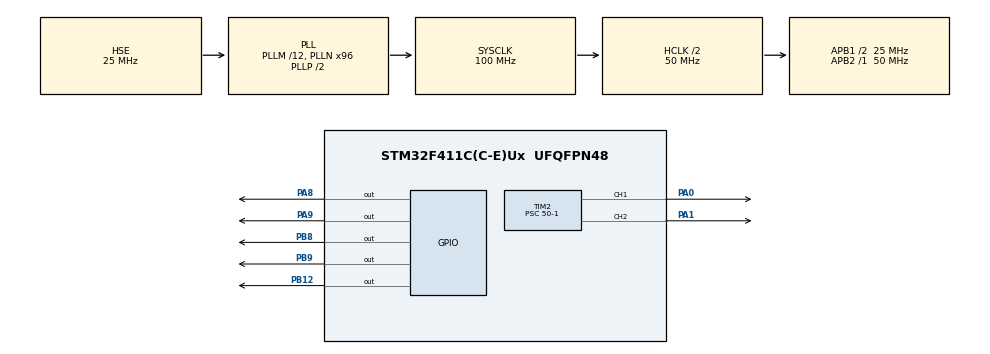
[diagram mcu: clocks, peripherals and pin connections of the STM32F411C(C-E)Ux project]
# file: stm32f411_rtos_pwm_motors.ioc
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FREERTOS.Tasks01=pwm01,24,128,startPwm01,Default,NULL,Dynamic,NULL,NULL;pwm02,8,128,startPwm02,Default,NULL,Dynamic,NULL,NULL;led01,8,128,startLed01,Default,NULL,Dynamic,NULL,NULL
FREERTOS.configUSE_NEWLIB_REENTRANT=1
Mcu.Family=STM32F4
Mcu.Name=STM32F411C(C-E)Ux
Mcu.Package=UFQFPN48
NVIC.PriorityGroup=NVIC_PRIORITYGROUP_4
NVIC.TIM5_IRQn=true\:15\:0\:false\:false\:true\:false\:false\:true\:true
NVIC.TimeBase=TIM5_IRQn
NVIC.TimeBaseIP=TIM5
PA0-WKUP.Signal=S_TIM2_CH1_ETR
PA1.Signal=S_TIM2_CH2
PA13.Mode=Serial_Wire
PA13.Signal=SYS_JTMS-SWDIO
PA14.Mode=Serial_Wire
PA14.Signal=SYS_JTCK-SWCLK
PA8.Signal=GPIO_Output
PA9.Signal=GPIO_Output
PB12.Signal=GPIO_Output
PB8.Signal=GPIO_Output
PB9.Signal=GPIO_Output
PH0\ -\ OSC_IN.Mode=HSE-External-Oscillator
PH0\ -\ OSC_IN.Signal=RCC_OSC_IN
PH1\ -\ OSC_OUT.Mode=HSE-External-Oscillator
PH1\ -\ OSC_OUT.Signal=RCC_OSC_OUT
ProjectManager.HeapSize=0x200
ProjectManager.StackSize=0x400
ProjectManager.TargetToolchain=STM32CubeIDE
RCC.48MHZClocksFreq_Value=50000000
RCC.AHBCLKDivider=RCC_SYSCLK_DIV2
RCC.AHBFreq_Value=50000000
RCC.APB1CLKDivider=RCC_HCLK_DIV2
RCC.APB1Freq_Value=25000000
RCC.APB1TimFreq_Value=50000000
RCC.APB2Freq_Value=50000000
RCC.APB2TimFreq_Value=50000000
RCC.CortexFreq_Value=50000000
RCC.HCLKFreq_Value=50000000
RCC.HSE_VALUE=25000000
RCC.HSI_VALUE=16000000
RCC.LSE_VALUE=32768
RCC.PLLM=12
RCC.PLLN=96
RCC.PLLSourceVirtual=RCC_PLLSOURCE_HSE
RCC.SYSCLKFreq_VALUE=100000000
RCC.SYSCLKSource=RCC_SYSCLKSOURCE_PLLCLK
RCC.VCOOutputFreq_Value=200000000
SH.S_TIM2_CH1_ETR.0=TIM2_CH1,PWM Generation1 CH1
SH.S_TIM2_CH2.0=TIM2_CH2,PWM Generation2 CH2
TIM2.Channel-PWM\ Generation1\ CH1=TIM_CHANNEL_1
TIM2.Channel-PWM\ Generation2\ CH2=TIM_CHANNEL_2
TIM2.Period=1000-1
TIM2.Prescaler=50-1
VP_FREERTOS_VS_CMSIS_V2.Mode=CMSIS_V2
VP_SYS_VS_tim5.Mode=TIM5
board=custom

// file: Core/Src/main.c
/* USER CODE BEGIN Header */
/**
  ******************************************************************************
  * @file           : main.c
  * @brief          : Main program body
  ******************************************************************************
  * @attention
  *
  * Copyright (c) 2023 STMicroelectronics.
  * All rights reserved.
  *
  * This software is licensed under terms that can be found in the LICENSE file
  * in the root directory of this software component.
  * If no LICENSE file comes with this software, it is provided AS-IS.
  *
  ******************************************************************************
  */
/* USER CODE END Header */
#include "main.h"
#include "cmsis_os.h"

/* USER CODE BEGIN PD */
// Define the size of the message queue
/* USER CODE END PD */

TIM_HandleTypeDef htim2;

/* Definitions for pwm01 */
osThreadId_t pwm01Handle;
const osThreadAttr_t pwm01_attributes = {
  .name = "pwm01",
  .stack_size = 128 * 4,
  .priority = (osPriority_t) osPriorityNormal,
};
/* Definitions for pwm02 */
osThreadId_t pwm02Handle;
const osThreadAttr_t pwm02_attributes = {
  .name = "pwm02",
  .stack_size = 128 * 4,
  .priority = (osPriority_t) osPriorityLow,
};
/* Definitions for led01 */
osThreadId_t led01Handle;
const osThreadAttr_t led01_attributes = {
  .name = "led01",
  .stack_size = 128 * 4,
  .priority = (osPriority_t) osPriorityLow,
};
/* USER CODE BEGIN PV */
// Structure to hold motor speed data

/* USER CODE END PV */

void SystemClock_Config(void);
static void MX_GPIO_Init(void);
static void MX_TIM2_Init(void);
void startPwm01(void *argument);
void startPwm02(void *argument);
void startLed01(void *argument);

int main(void)
{

  /* MCU Configuration--------------------------------------------------------*/

  /* Reset of all peripherals, Initializes the Flash interface and the Systick. */
  HAL_Init();

  /* Configure the system clock */
  SystemClock_Config();

  /* Initialize all configured peripherals */
  MX_GPIO_Init();
  MX_TIM2_Init();

  /* Init scheduler */
  osKernelInitialize();

  /* Create the thread(s) */
  /* creation of pwm01 */
  pwm01Handle = osThreadNew(startPwm01, NULL, &pwm01_attributes);

  /* creation of pwm02 */
  pwm02Handle = osThreadNew(startPwm02, NULL, &pwm02_attributes);

  /* creation of led01 */
  led01Handle = osThreadNew(startLed01, NULL, &led01_attributes);

  /* Start scheduler */
  osKernelStart();

  /* We should never get here as control is now taken by the scheduler */
  /* Infinite loop */
  while (1)
  {

  }
}

void SystemClock_Config(void)
{
  RCC_OscInitTypeDef RCC_OscInitStruct = {0};
  RCC_ClkInitTypeDef RCC_ClkInitStruct = {0};

  /** Configure the main internal regulator output voltage
  */
  __HAL_RCC_PWR_CLK_ENABLE();
  __HAL_PWR_VOLTAGESCALING_CONFIG(PWR_REGULATOR_VOLTAGE_SCALE1);

  /** Initializes the RCC Oscillators according to the specified parameters
  * in the RCC_OscInitTypeDef structure.
  */
  RCC_OscInitStruct.OscillatorType = RCC_OSCILLATORTYPE_HSE;
  RCC_OscInitStruct.HSEState = RCC_HSE_ON;
  RCC_OscInitStruct.PLL.PLLState = RCC_PLL_ON;
  RCC_OscInitStruct.PLL.PLLSource = RCC_PLLSOURCE_HSE;
  RCC_OscInitStruct.PLL.PLLM = 12;
  RCC_OscInitStruct.PLL.PLLN = 96;
  RCC_OscInitStruct.PLL.PLLP = RCC_PLLP_DIV2;
  RCC_OscInitStruct.PLL.PLLQ = 4;
  if (HAL_RCC_OscConfig(&RCC_OscInitStruct) != HAL_OK)
  {
    Error_Handler();
  }

  /** Initializes the CPU, AHB and APB buses clocks
  */
  RCC_ClkInitStruct.ClockType = RCC_CLOCKTYPE_HCLK|RCC_CLOCKTYPE_SYSCLK
                              |RCC_CLOCKTYPE_PCLK1|RCC_CLOCKTYPE_PCLK2;
  RCC_ClkInitStruct.SYSCLKSource = RCC_SYSCLKSOURCE_PLLCLK;
  RCC_ClkInitStruct.AHBCLKDivider = RCC_SYSCLK_DIV2;
  RCC_ClkInitStruct.APB1CLKDivider = RCC_HCLK_DIV2;
  RCC_ClkInitStruct.APB2CLKDivider = RCC_HCLK_DIV1;

  if (HAL_RCC_ClockConfig(&RCC_ClkInitStruct, FLASH_LATENCY_1) != HAL_OK)
  {
    Error_Handler();
  }
}

static void MX_TIM2_Init(void)
{

  TIM_MasterConfigTypeDef sMasterConfig = {0};
  TIM_OC_InitTypeDef sConfigOC = {0};

  htim2.Instance = TIM2;
  htim2.Init.Prescaler = 50-1;
  htim2.Init.CounterMode = TIM_COUNTERMODE_UP;
  htim2.Init.Period = 1000-1;
  htim2.Init.ClockDivision = TIM_CLOCKDIVISION_DIV1;
  htim2.Init.AutoReloadPreload = TIM_AUTORELOAD_PRELOAD_DISABLE;
  if (HAL_TIM_PWM_Init(&htim2) != HAL_OK)
  {
    Error_Handler();
  }
  sMasterConfig.MasterOutputTrigger = TIM_TRGO_RESET;
  sMasterConfig.MasterSlaveMode = TIM_MASTERSLAVEMODE_DISABLE;
  if (HAL_TIMEx_MasterConfigSynchronization(&htim2, &sMasterConfig) != HAL_OK)
  {
    Error_Handler();
  }
  sConfigOC.OCMode = TIM_OCMODE_PWM1;
  sConfigOC.Pulse = 0;
  sConfigOC.OCPolarity = TIM_OCPOLARITY_HIGH;
  sConfigOC.OCFastMode = TIM_OCFAST_DISABLE;
  if (HAL_TIM_PWM_ConfigChannel(&htim2, &sConfigOC, TIM_CHANNEL_1) != HAL_OK)
  {
    Error_Handler();
  }
  if (HAL_TIM_PWM_ConfigChannel(&htim2, &sConfigOC, TIM_CHANNEL_2) != HAL_OK)
  {
    Error_Handler();
  }
  HAL_TIM_MspPostInit(&htim2);

}

static void MX_GPIO_Init(void)
{
  GPIO_InitTypeDef GPIO_InitStruct = {0};

  /* GPIO Ports Clock Enable */
  __HAL_RCC_GPIOH_CLK_ENABLE();
  __HAL_RCC_GPIOA_CLK_ENABLE();
  __HAL_RCC_GPIOB_CLK_ENABLE();

  /*Configure GPIO pin Output Level */
  HAL_GPIO_WritePin(GPIOB, GPIO_PIN_12|GPIO_PIN_8|GPIO_PIN_9, GPIO_PIN_RESET);

  /*Configure GPIO pin Output Level */
  HAL_GPIO_WritePin(GPIOA, GPIO_PIN_8|GPIO_PIN_9, GPIO_PIN_RESET);

  /*Configure GPIO pins : PB12 PB8 PB9 */
  GPIO_InitStruct.Pin = GPIO_PIN_12|GPIO_PIN_8|GPIO_PIN_9;
  GPIO_InitStruct.Mode = GPIO_MODE_OUTPUT_PP;
  GPIO_InitStruct.Pull = GPIO_NOPULL;
  GPIO_InitStruct.Speed = GPIO_SPEED_FREQ_LOW;
  HAL_GPIO_Init(GPIOB, &GPIO_InitStruct);

  /*Configure GPIO pins : PA8 PA9 */
  GPIO_InitStruct.Pin = GPIO_PIN_8|GPIO_PIN_9;
  GPIO_InitStruct.Mode = GPIO_MODE_OUTPUT_PP;
  GPIO_InitStruct.Pull = GPIO_NOPULL;
  GPIO_InitStruct.Speed = GPIO_SPEED_FREQ_LOW;
  HAL_GPIO_Init(GPIOA, &GPIO_InitStruct);

}

void startPwm01(void *argument)
{
  /* USER CODE BEGIN 5 */
  /* Infinite loop */
  for(;;)
  {
      // Use data.motor1Speed to control motor 1
      // Implement your motor control logic here
	  TIM2 ->CCR1 = 500;
	  HAL_TIM_PWM_Start(&htim2, TIM_CHANNEL_1);
	  osDelay(30);
  }
  /* USER CODE END 5 */
}

void startPwm02(void *argument)
{
  /* USER CODE BEGIN startPwm02 */
  /* Infinite loop */
  for(;;)
  {
	TIM2 ->CCR2 = 500;
	HAL_TIM_PWM_Start(&htim2, TIM_CHANNEL_2);
    osDelay(30);
  }
  /* USER CODE END startPwm02 */
}

void startLed01(void *argument)
{
  /* USER CODE BEGIN startLed01 */
  /* Infinite loop */
  for(;;)
  {
	HAL_GPIO_TogglePin(GPIOB, GPIO_PIN_12);
    osDelay(300);
  }
  /* USER CODE END startLed01 */
}

void HAL_TIM_PeriodElapsedCallback(TIM_HandleTypeDef *htim)
{
  if (htim->Instance == TIM5) {
    HAL_IncTick();
  }
}

void Error_Handler(void)
{
  __disable_irq();
  while (1)
  {
  }
}
